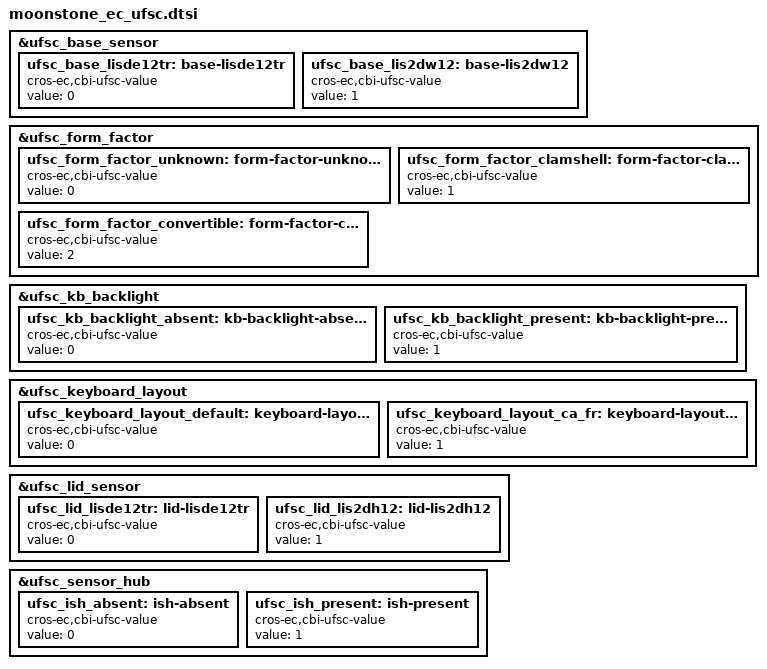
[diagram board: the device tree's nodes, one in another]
/* Copyright 2025 The ChromiumOS Authors
 * Use of this source code is governed by a BSD-style license that can be
 * found in the LICENSE file.
 */

/* Auto-generated by generate_ufsc.py */

&ufsc_base_sensor {
	ufsc_base_lisde12tr: base-lisde12tr {
		compatible = "cros-ec,cbi-ufsc-value";
		status = "okay";
		value = <0>;
	};
	ufsc_base_lis2dw12: base-lis2dw12 {
		compatible = "cros-ec,cbi-ufsc-value";
		status = "okay";
		value = <1>;
	};
};

&ufsc_form_factor {
	ufsc_form_factor_unknown: form-factor-unknown {
		compatible = "cros-ec,cbi-ufsc-value";
		status = "okay";
		value = <0>;
	};
	ufsc_form_factor_clamshell: form-factor-clamshell {
		compatible = "cros-ec,cbi-ufsc-value";
		status = "okay";
		value = <1>;
	};
	ufsc_form_factor_convertible: form-factor-convertible {
		compatible = "cros-ec,cbi-ufsc-value";
		status = "okay";
		value = <2>;
	};
};

&ufsc_kb_backlight {
	ufsc_kb_backlight_absent: kb-backlight-absent {
		compatible = "cros-ec,cbi-ufsc-value";
		status = "okay";
		value = <0>;
	};
	ufsc_kb_backlight_present: kb-backlight-present {
		compatible = "cros-ec,cbi-ufsc-value";
		status = "okay";
		value = <1>;
	};
};

&ufsc_keyboard_layout {
	ufsc_keyboard_layout_default: keyboard-layout-default {
		compatible = "cros-ec,cbi-ufsc-value";
		status = "okay";
		value = <0>;
	};
	ufsc_keyboard_layout_ca_fr: keyboard-layout-ca-fr {
		compatible = "cros-ec,cbi-ufsc-value";
		status = "okay";
		value = <1>;
	};
};

&ufsc_lid_sensor {
	ufsc_lid_lisde12tr: lid-lisde12tr {
		compatible = "cros-ec,cbi-ufsc-value";
		status = "okay";
		value = <0>;
	};
	ufsc_lid_lis2dh12: lid-lis2dh12 {
		compatible = "cros-ec,cbi-ufsc-value";
		status = "okay";
		value = <1>;
	};
};

&ufsc_sensor_hub {
	ufsc_ish_absent: ish-absent {
		compatible = "cros-ec,cbi-ufsc-value";
		status = "okay";
		value = <0>;
	};
	ufsc_ish_present: ish-present {
		compatible = "cros-ec,cbi-ufsc-value";
		status = "okay";
		value = <1>;
	};
};
